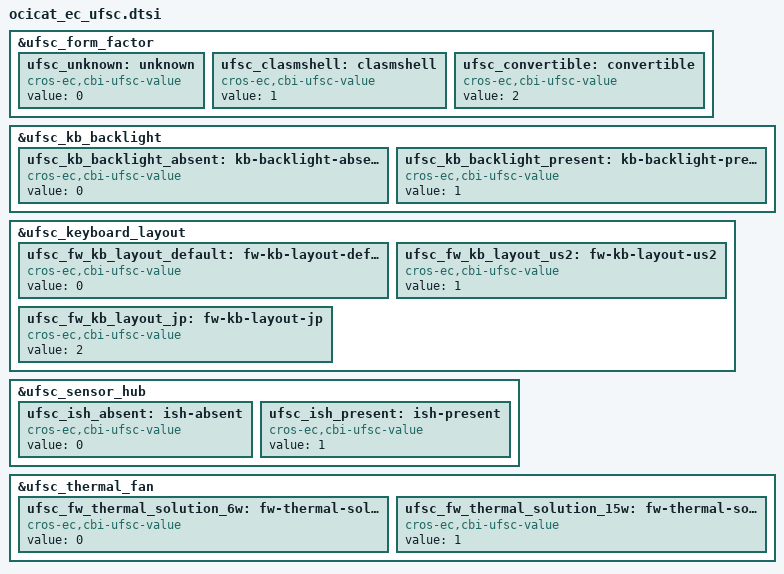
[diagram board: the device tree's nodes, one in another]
/* Auto-generated by generate_ufsc.py */

&ufsc_form_factor {
	ufsc_unknown: unknown {
		compatible = "cros-ec,cbi-ufsc-value";
		status = "okay";
		value = <0>;
	};
	ufsc_clasmshell: clasmshell {
		compatible = "cros-ec,cbi-ufsc-value";
		status = "okay";
		value = <1>;
	};
	ufsc_convertible: convertible {
		compatible = "cros-ec,cbi-ufsc-value";
		status = "okay";
		value = <2>;
	};
};

&ufsc_kb_backlight {
	ufsc_kb_backlight_absent: kb-backlight-absent {
		compatible = "cros-ec,cbi-ufsc-value";
		status = "okay";
		value = <0>;
	};
	ufsc_kb_backlight_present: kb-backlight-present {
		compatible = "cros-ec,cbi-ufsc-value";
		status = "okay";
		value = <1>;
	};
};

&ufsc_keyboard_layout {
	ufsc_fw_kb_layout_default: fw-kb-layout-default {
		compatible = "cros-ec,cbi-ufsc-value";
		status = "okay";
		value = <0>;
	};
	ufsc_fw_kb_layout_us2: fw-kb-layout-us2 {
		compatible = "cros-ec,cbi-ufsc-value";
		status = "okay";
		value = <1>;
	};
	ufsc_fw_kb_layout_jp: fw-kb-layout-jp {
		compatible = "cros-ec,cbi-ufsc-value";
		status = "okay";
		value = <2>;
	};
};

&ufsc_sensor_hub {
	ufsc_ish_absent: ish-absent {
		compatible = "cros-ec,cbi-ufsc-value";
		status = "okay";
		value = <0>;
	};
	ufsc_ish_present: ish-present {
		compatible = "cros-ec,cbi-ufsc-value";
		status = "okay";
		value = <1>;
	};
};

&ufsc_thermal_fan {
	ufsc_fw_thermal_solution_6w: fw-thermal-solution-6w {
		compatible = "cros-ec,cbi-ufsc-value";
		status = "okay";
		value = <0>;
	};
	ufsc_fw_thermal_solution_15w: fw-thermal-solution-15w {
		compatible = "cros-ec,cbi-ufsc-value";
		status = "okay";
		value = <1>;
	};
};


